# nrf54h20_engb_sysctrl register map
Vendor: Nordic Semiconductor; Series: nRF54h; File version: 1
Registers are 32-bit, read-write, reset 0x0 unless marked. A register's access mark holds for its fields unless they carry their own. Offsets are from the block's base; [hi:lo] are bit positions; lines under a group give offsets from that group; {n}, {i} and the like mark numbered series.

## L2CACHEDATA — CACHEDATA
Base 0x3F640000
{0x0+0x80*i} SET[{i}] (i=0..1023) group — Unspecified
  {0x0+0x40*j} WAY[{j}] (j=0..1) group — Unspecified
    {0x0+0x10*k} DU[{k}] (k=0..3) group — Unspecified
      {0x0+4l} DATA[{l}] (l=0..3) — Description collection: Cache data bits for DATA[q] in DU[p] (DataUnit) of SET[n], WAY[o].
        [31:0] Data ro

## L2CACHEINFO — CACHEINFO
Base 0x3F680000
{0x0+8i} SET[{i}] (i=0..1023) group — Unspecified
  {0x0+4j} WAY[{j}] (j=0..1) group — Unspecified
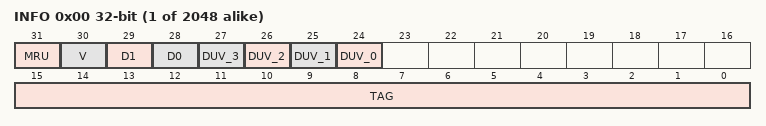
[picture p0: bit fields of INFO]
    0x00 INFO — Description cluster: Cache information for SET[n], WAY[o].
      [31] MRU ro — Most recently used way.
        0=Way0 was most recently used; 1=Way1 was most recently used
      [30] V ro — Line valid bit.
        0=Invalid cache line; 1=Valid cache line
      [29] D1 ro — Dirty status of combined data unit 2 and 3.
        0=Clean data unit; 1=Dirty data unit
      [28] D0 ro — Dirty status of combined data unit 0 and 1.
        0=Clean data unit; 1=Dirty data unit
      [n+24] DUV_{n} ro (n=0..3) — Data unit valid info.
        0=Invalid data unit; 1=Valid data unit
      [15:0] TAG ro — Cache tag.

## SHA3CORE — CRACENCORE
Base 0x5F089000
0x00 CRYPTMSTRDMA group — Unspecified
  0x00 FETCHADDRLSB — Fetch Address Least Significant Bit
  0x04 FETCHADDRMSB — Fetch Address Most Significant Bit
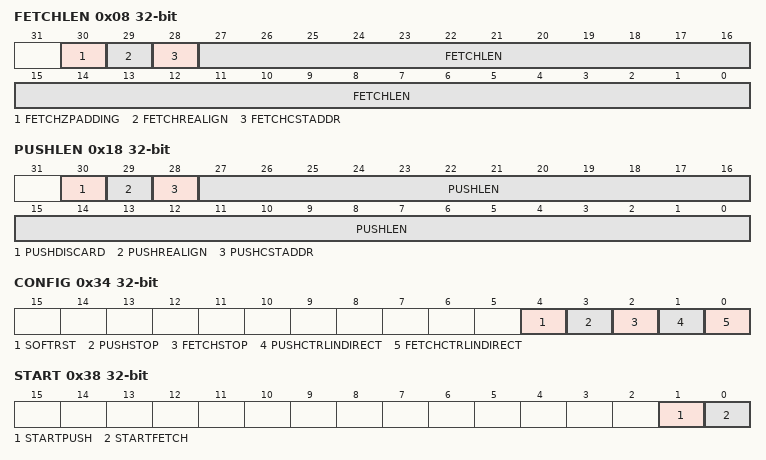
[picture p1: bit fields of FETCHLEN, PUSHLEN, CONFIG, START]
  0x08 FETCHLEN — Fetch Length
    [30] FETCHZPADDING, [29] FETCHREALIGN, [28] FETCHCSTADDR, [27:0] FETCHLEN
  0x0C FETCHTAG
  0x10 PUSHADDRLSB — Push Address Least Significant Bit
  0x14 PUSHADDRMSB — Push Address Most Significant Bit
  0x18 PUSHLEN — Push Length
    [30] PUSHDISCARD, [29] PUSHREALIGN, [28] PUSHCSTADDR, [27:0] PUSHLEN
  0x1C INTEN — Interrupt Enable
    [5:0] INTEN
  0x20 INTENSET — Interrupt Set
    [5:0] INTENSET wo
  0x24 INTENCLR — Interrupt Clear
    [5:0] INTENCLR wo
  0x28 INTSTATRAW — Interrupt Status Raw
    [31:0] INTSTATRAW ro
  0x2C INTSTAT — Interrupt Status
    [31:0] INTSTAT ro
  0x30 INTSTATCLR — Interrupt Status Clear
    [31:0] INTSTATCLR wo
  0x34 CONFIG — Configuration
    [4] SOFTRST, [3] PUSHSTOP, [2] FETCHSTOP, [1] PUSHCTRLINDIRECT, [0] FETCHCTRLINDIRECT
  0x38 START
    [1] STARTPUSH wo, [0] STARTFETCH wo
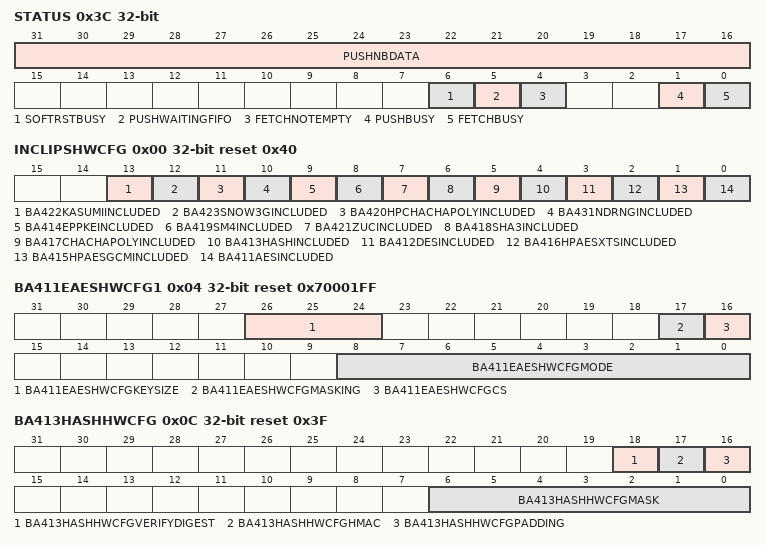
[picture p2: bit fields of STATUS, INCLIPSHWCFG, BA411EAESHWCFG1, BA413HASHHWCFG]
  0x3C STATUS
    [31:16] PUSHNBDATA ro, [6] SOFTRSTBUSY ro, [5] PUSHWAITINGFIFO ro, [4] FETCHNOTEMPTY ro, [1] PUSHBUSY ro, [0] FETCHBUSY ro
0x400 CRYPTMSTRHW group — Unspecified
  0x00 INCLIPSHWCFG reset 0x40 — Incuded IPs Hardware configuration
    [13] BA422KASUMIINCLUDED ro — Generic g_IncludeKasumi value.
    [12] BA423SNOW3GINCLUDED ro — Generic g_IncludeSnow3G value.
    [11] BA420HPCHACHAPOLYINCLUDED ro — Generic g_IncludeHPChachaPoly value.
    [10] BA431NDRNGINCLUDED ro — Generic g_IncludeNDRNG value.
    [9] BA414EPPKEINCLUDED ro — Generic g_IncludePKE value.
    [8] BA419SM4INCLUDED ro — Generic g_IncludeSM4 value.
    [7] BA421ZUCINCLUDED ro — Generic g_IncludeZUC value.
    [6] BA418SHA3INCLUDED ro — Generic g_IncludeSHA3 value.
    [5] BA417CHACHAPOLYINCLUDED ro — Generic g_IncludeChachaPoly value.
    [4] BA413HASHINCLUDED ro — Generic g_IncludeHASH value.
    [3] BA412DESINCLUDED ro — Generic g_IncludeDES value.
    [2] BA416HPAESXTSINCLUDED ro — Generic g_IncludeAESXTS value.
    [1] BA415HPAESGCMINCLUDED ro — Generic g_IncludeAESGCM value.
    [0] BA411AESINCLUDED ro — Generic g_IncludeAES value.
  0x04 BA411EAESHWCFG1 reset 0x70001FF — Generic g_AesModesPoss value.
    [26:24] BA411EAESHWCFGKEYSIZE ro — Generic g_Keysize value.
    [17] BA411EAESHWCFGMASKING ro — Generic g_UseMasking value.
    [16] BA411EAESHWCFGCS ro — Generic g_CS value.
    [8:0] BA411EAESHWCFGMODE ro — Generic g_AesModesPoss value.
  0x08 BA411EAESHWCFG2 reset 0x80 — Generic g_CtrSize value.
    [15:0] BA411EAESHWCFG2 ro
  0x0C BA413HASHHWCFG reset 0x3F — Generic g_Hash value
    [18] BA413HASHHWCFGVERIFYDIGEST ro — Generic g_HashVerifyDigest value.
    [17] BA413HASHHWCFGHMAC ro — Generic g_HMAC_enabled value.
    [16] BA413HASHHWCFGPADDING ro — Generic g_HashPadding value.
    [6:0] BA413HASHHWCFGMASK ro — Generic g_HashMaskFunc value.
  0x10 BA418SHA3HWCFG reset 0x1 — Generic g_Sha3CtxtEn value.
    [0] BA418SHA3HWCFG ro
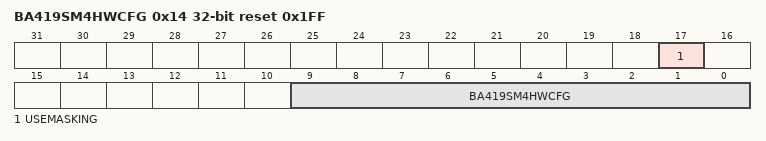
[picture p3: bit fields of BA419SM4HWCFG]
  0x14 BA419SM4HWCFG reset 0x1FF — Generic g_SM4ModesPoss value.
    [17] USEMASKING ro — Generic g_sm4UseMasking value.
    [9:0] BA419SM4HWCFG ro — Generic g_SM4ModesPoss value.
  0x18 BA424ARIAHWCFG reset 0x17F — Generic g_aria_modePoss value.
    [8:0] BA424ARIAHWCFG ro
